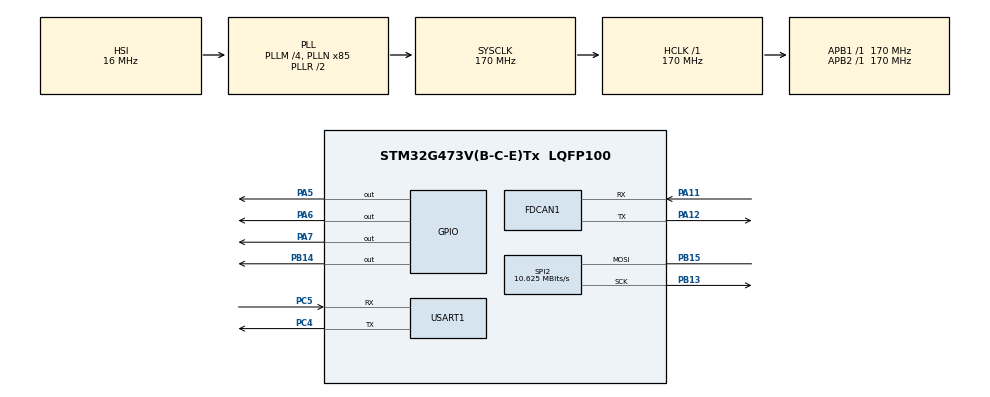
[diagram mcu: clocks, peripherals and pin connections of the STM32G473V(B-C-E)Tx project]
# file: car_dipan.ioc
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FDCAN1.CalculateBaudRateNominal=3541666
FDCAN1.CalculateTimeBitNominal=282
FDCAN1.CalculateTimeQuantumNominal=94.11764705882354
Mcu.Family=STM32G4
Mcu.Name=STM32G473V(B-C-E)Tx
Mcu.Package=LQFP100
NVIC.PriorityGroup=NVIC_PRIORITYGROUP_4
PA11.Mode=FDCAN_Activate
PA11.Signal=FDCAN1_RX
PA12.Mode=FDCAN_Activate
PA12.Signal=FDCAN1_TX
PA5.Signal=GPIO_Output
PA6.Signal=GPIO_Output
PA7.Signal=GPIO_Output
PB13.Mode=Simplex_Bidirectional_Master
PB13.Signal=SPI2_SCK
PB14.Signal=GPIO_Output
PB15.Mode=Simplex_Bidirectional_Master
PB15.Signal=SPI2_MOSI
PC4.Mode=Asynchronous
PC4.Signal=USART1_TX
PC5.Mode=Asynchronous
PC5.Signal=USART1_RX
ProjectManager.HeapSize=0x200
ProjectManager.StackSize=0x400
ProjectManager.TargetToolchain=MDK-ARM V5.32
RCC.ADC12Freq_Value=170000000
RCC.ADC345Freq_Value=170000000
RCC.AHBFreq_Value=170000000
RCC.APB1Freq_Value=170000000
RCC.APB1TimFreq_Value=170000000
RCC.APB2Freq_Value=170000000
RCC.APB2TimFreq_Value=170000000
RCC.CortexFreq_Value=170000000
RCC.EXTERNAL_CLOCK_VALUE=12288000
RCC.HCLKFreq_Value=170000000
RCC.HSE_VALUE=8000000
RCC.HSI48_VALUE=48000000
RCC.HSI_VALUE=16000000
RCC.LSE_VALUE=32768
RCC.PLLM=RCC_PLLM_DIV4
RCC.PLLN=85
RCC.SYSCLKFreq_VALUE=170000000
RCC.SYSCLKSource=RCC_SYSCLKSOURCE_PLLCLK
RCC.USBFreq_Value=170000000
RCC.VCOOutputFreq_Value=340000000
SPI2.BaudRatePrescaler=SPI_BAUDRATEPRESCALER_16
SPI2.CLKPhase=SPI_PHASE_2EDGE
SPI2.CLKPolarity=SPI_POLARITY_HIGH
SPI2.CalculateBaudRate=10.625 MBits/s
SPI2.DataSize=SPI_DATASIZE_8BIT
SPI2.Direction=SPI_DIRECTION_1LINE
SPI2.Mode=SPI_MODE_MASTER
SPI2.VirtualType=VM_MASTER
USART1.VirtualMode-Asynchronous=VM_ASYNC
VP_SYS_VS_DBSignals.Mode=DisableDeadBatterySignals
board=custom

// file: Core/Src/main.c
/* USER CODE BEGIN Header */
/**
  ******************************************************************************
  * @file           : main.c
  * @brief          : Main program body
  ******************************************************************************
  * @attention
  *
  * Copyright (c) 2026 STMicroelectronics.
  * All rights reserved.
  *
  * This software is licensed under terms that can be found in the LICENSE file
  * in the root directory of this software component.
  * If no LICENSE file comes with this software, it is provided AS-IS.
  *
  ******************************************************************************
  */
/* USER CODE END Header */
#include "main.h"
#include "fdcan.h"
#include "spi.h"
#include "usart.h"
#include "gpio.h"

/* USER CODE BEGIN Includes */
#include "lcd.h"
/* USER CODE END Includes */

void SystemClock_Config(void);

int main(void)
{

  /* MCU Configuration--------------------------------------------------------*/

  /* Reset of all peripherals, Initializes the Flash interface and the Systick. */
  HAL_Init();

  /* Configure the system clock */
  SystemClock_Config();

  /* Initialize all configured peripherals */
  MX_GPIO_Init();
  MX_USART1_UART_Init();
  MX_SPI2_Init();
  MX_FDCAN1_Init();
  /* USER CODE BEGIN 2 */
  /* 屏幕初始化（ST7789 2.00寸 320x240），并显示一行字 */
  LCD_Init();
  LCD_ShowString(128, 112, "我是G473", GREEN, BLACK);
  /* USER CODE END 2 */

  /* Infinite loop */
  while (1)
  {

  }
}

void SystemClock_Config(void)
{
  RCC_OscInitTypeDef RCC_OscInitStruct = {0};
  RCC_ClkInitTypeDef RCC_ClkInitStruct = {0};

  /** Configure the main internal regulator output voltage
  */
  HAL_PWREx_ControlVoltageScaling(PWR_REGULATOR_VOLTAGE_SCALE1_BOOST);

  /** Initializes the RCC Oscillators according to the specified parameters
  * in the RCC_OscInitTypeDef structure.
  */
  RCC_OscInitStruct.OscillatorType = RCC_OSCILLATORTYPE_HSI;
  RCC_OscInitStruct.HSIState = RCC_HSI_ON;
  RCC_OscInitStruct.HSICalibrationValue = RCC_HSICALIBRATION_DEFAULT;
  RCC_OscInitStruct.PLL.PLLState = RCC_PLL_ON;
  RCC_OscInitStruct.PLL.PLLSource = RCC_PLLSOURCE_HSI;
  RCC_OscInitStruct.PLL.PLLM = RCC_PLLM_DIV4;
  RCC_OscInitStruct.PLL.PLLN = 85;
  RCC_OscInitStruct.PLL.PLLP = RCC_PLLP_DIV2;
  RCC_OscInitStruct.PLL.PLLQ = RCC_PLLQ_DIV2;
  RCC_OscInitStruct.PLL.PLLR = RCC_PLLR_DIV2;
  if (HAL_RCC_OscConfig(&RCC_OscInitStruct) != HAL_OK)
  {
    Error_Handler();
  }

  /** Initializes the CPU, AHB and APB buses clocks
  */
  RCC_ClkInitStruct.ClockType = RCC_CLOCKTYPE_HCLK|RCC_CLOCKTYPE_SYSCLK
                              |RCC_CLOCKTYPE_PCLK1|RCC_CLOCKTYPE_PCLK2;
  RCC_ClkInitStruct.SYSCLKSource = RCC_SYSCLKSOURCE_PLLCLK;
  RCC_ClkInitStruct.AHBCLKDivider = RCC_SYSCLK_DIV1;
  RCC_ClkInitStruct.APB1CLKDivider = RCC_HCLK_DIV1;
  RCC_ClkInitStruct.APB2CLKDivider = RCC_HCLK_DIV1;

  if (HAL_RCC_ClockConfig(&RCC_ClkInitStruct, FLASH_LATENCY_4) != HAL_OK)
  {
    Error_Handler();
  }
}

void Error_Handler(void)
{
  __disable_irq();
  while (1)
  {
  }
}
